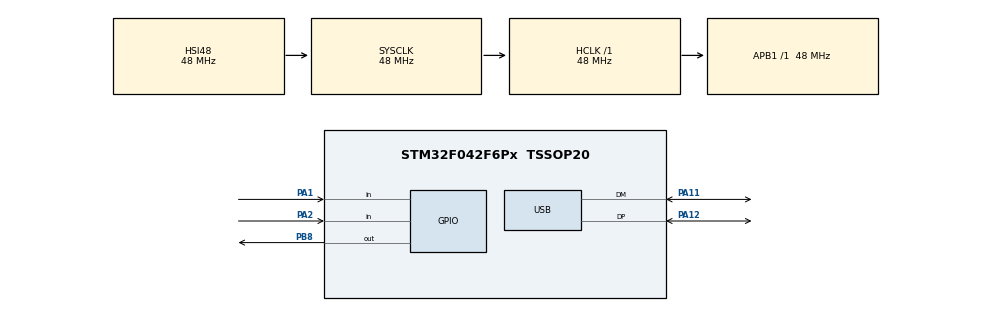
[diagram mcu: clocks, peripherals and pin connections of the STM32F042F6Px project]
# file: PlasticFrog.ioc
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Mcu.Family=STM32F0
Mcu.Name=STM32F042F6Px
Mcu.Package=TSSOP20
NVIC.TIM1_BRK_UP_TRG_COM_IRQn=true\:0\:0\:false\:false\:true\:false\:true
NVIC.TimeBase=TIM1_BRK_UP_TRG_COM_IRQn
NVIC.TimeBaseIP=TIM1
NVIC.USB_IRQn=true\:0\:0\:false\:false\:true\:false\:true
PA1.Signal=GPIO_Input
PA11.Mode=Device
PA11.Signal=USB_DM
PA12.Mode=Device
PA12.Signal=USB_DP
PA2.Signal=GPIO_Input
PB8.Signal=GPIO_Output
ProjectManager.HeapSize=0x200
ProjectManager.StackSize=0x400
ProjectManager.TargetToolchain=Makefile
RCC.AHBFreq_Value=48000000
RCC.APB1Freq_Value=48000000
RCC.APB1TimFreq_Value=48000000
RCC.HCLKFreq_Value=48000000
RCC.SYSCLKFreq_VALUE=48000000
RCC.SYSCLKSource=RCC_SYSCLKSOURCE_HSI48
USB_DEVICE.CLASS_NAME_FS=HID
USB_DEVICE.VirtualMode=Hid
USB_DEVICE.VirtualModeFS=Hid_FS
VP_SYS_VS_PINREMAP.Mode=PINREMAP
VP_SYS_VS_tim1.Mode=TIM1
VP_USB_DEVICE_VS_USB_DEVICE_HID_FS.Mode=HID_FS
board=custom

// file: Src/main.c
/* USER CODE BEGIN Header */
/**
  ******************************************************************************
  * @file           : main.c
  * @brief          : Main program body
  ******************************************************************************
  * @attention
  *
  * <h2><center>&copy; Copyright (c) 2019 STMicroelectronics.
  * All rights reserved.</center></h2>
  *
  * This software component is licensed by ST under Ultimate Liberty license
  * SLA0044, the "License"; You may not use this file except in compliance with
  * the License. You may obtain a copy of the License at:
  *                             www.st.com/SLA0044
  *
  ******************************************************************************
  */
/* USER CODE END Header */

#include "main.h"
#include "usb_device.h"

/* USER CODE BEGIN PD */

#define CLICK_REPORT_SIZE 8
uint8_t click_report[CLICK_REPORT_SIZE] = {0};
/* USER CODE END PD */

/* USER CODE BEGIN PV */

extern USBD_HandleTypeDef hUsbDeviceFS;

/* USER CODE END PV */

void SystemClock_Config(void);
static void MX_GPIO_Init(void);

int main(void)
{

  /* MCU Configuration--------------------------------------------------------*/

  /* Reset of all peripherals, Initializes the Flash interface and the Systick. */
  HAL_Init();

  /* Configure the system clock */
  SystemClock_Config();

  /* Initialize all configured peripherals */
  MX_GPIO_Init();
  MX_USB_DEVICE_Init();

  /* Infinite loop */
  while (1)
  {
click_report[2] = 0x65; // send button press
USBD_HID_SendReport(&hUsbDeviceFS, click_report, CLICK_REPORT_SIZE);
HAL_Delay(50);

click_report[2] = 0; // send button release
USBD_HID_SendReport(&hUsbDeviceFS, click_report, CLICK_REPORT_SIZE);

HAL_Delay(200);

  }
}

void SystemClock_Config(void)
{
  RCC_OscInitTypeDef RCC_OscInitStruct = {0};
  RCC_ClkInitTypeDef RCC_ClkInitStruct = {0};
  RCC_PeriphCLKInitTypeDef PeriphClkInit = {0};

  /** Initializes the CPU, AHB and APB busses clocks
  */
  RCC_OscInitStruct.OscillatorType = RCC_OSCILLATORTYPE_HSI48;
  RCC_OscInitStruct.HSI48State = RCC_HSI48_ON;
  RCC_OscInitStruct.PLL.PLLState = RCC_PLL_NONE;
  if (HAL_RCC_OscConfig(&RCC_OscInitStruct) != HAL_OK)
  {
    Error_Handler();
  }
  /** Initializes the CPU, AHB and APB busses clocks
  */
  RCC_ClkInitStruct.ClockType = RCC_CLOCKTYPE_HCLK|RCC_CLOCKTYPE_SYSCLK
                              |RCC_CLOCKTYPE_PCLK1;
  RCC_ClkInitStruct.SYSCLKSource = RCC_SYSCLKSOURCE_HSI48;
  RCC_ClkInitStruct.AHBCLKDivider = RCC_SYSCLK_DIV1;
  RCC_ClkInitStruct.APB1CLKDivider = RCC_HCLK_DIV1;

  if (HAL_RCC_ClockConfig(&RCC_ClkInitStruct, FLASH_LATENCY_1) != HAL_OK)
  {
    Error_Handler();
  }
  PeriphClkInit.PeriphClockSelection = RCC_PERIPHCLK_USB;
  PeriphClkInit.UsbClockSelection = RCC_USBCLKSOURCE_HSI48;

  if (HAL_RCCEx_PeriphCLKConfig(&PeriphClkInit) != HAL_OK)
  {
    Error_Handler();
  }
}

static void MX_GPIO_Init(void)
{
  GPIO_InitTypeDef GPIO_InitStruct = {0};

  /* GPIO Ports Clock Enable */
  __HAL_RCC_GPIOB_CLK_ENABLE();
  __HAL_RCC_GPIOA_CLK_ENABLE();

  /*Configure GPIO pin Output Level */
  HAL_GPIO_WritePin(GPIOB, GPIO_PIN_8, GPIO_PIN_RESET);

  /*Configure GPIO pin : PB8 */
  GPIO_InitStruct.Pin = GPIO_PIN_8;
  GPIO_InitStruct.Mode = GPIO_MODE_OUTPUT_PP;
  GPIO_InitStruct.Pull = GPIO_NOPULL;
  GPIO_InitStruct.Speed = GPIO_SPEED_FREQ_LOW;
  HAL_GPIO_Init(GPIOB, &GPIO_InitStruct);

  /*Configure GPIO pins : PA1 PA2 */
  GPIO_InitStruct.Pin = GPIO_PIN_1|GPIO_PIN_2;
  GPIO_InitStruct.Mode = GPIO_MODE_INPUT;
  GPIO_InitStruct.Pull = GPIO_NOPULL;
  HAL_GPIO_Init(GPIOA, &GPIO_InitStruct);

}

void HAL_TIM_PeriodElapsedCallback(TIM_HandleTypeDef *htim)
{
  if (htim->Instance == TIM1) {
    HAL_IncTick();
  }
}

void Error_Handler(void)
{
}

/************************ (C) COPYRIGHT STMicroelectronics *****END OF FILE****/
